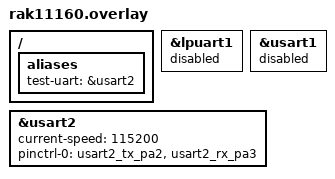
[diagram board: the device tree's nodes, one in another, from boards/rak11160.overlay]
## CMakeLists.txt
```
# SPDX-License-Identifier: Apache-2.0

cmake_minimum_required(VERSION 3.20.0)

find_package(Zephyr REQUIRED HINTS $ENV{ZEPHYR_BASE})
project(uart_sleep)

target_sources(app PRIVATE src/main.c)
target_sources_ifdef(CONFIG_BT_PERIPHERAL app PRIVATE src/rak_ble_peripheral.c)
if(CONFIG_USE_SEGGER_RTT AND CONFIG_BOARD_RAK11720)
  target_sources(app PRIVATE src/rtt.c)
endif()
```

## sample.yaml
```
sample:
  name: UART Sleep
tests:
  sample.basic.uart_sleep:
    platform_allow:
      - rak3172
      - rak4631
      - rak11160
    tags: rak
    build_only: true
  sample.basic.uart_sleep.ble:
    platform_allow:
      - rak11720
    extra_args: EXTRA_CONF_FILE=overlay_ble.conf
    tags: rak
    build_only: true
```

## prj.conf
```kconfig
CONFIG_SERIAL=y
CONFIG_UART_INTERRUPT_DRIVEN=y

CONFIG_GPIO=y
CONFIG_SPI=y
CONFIG_LORA=y

CONFIG_CONSOLE=n
CONFIG_UART_CONSOLE=n

CONFIG_PINCTRL=y
CONFIG_PM=y
CONFIG_PM_DEVICE=y

CONFIG_LOG=n
```

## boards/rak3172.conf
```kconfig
# Necessary options for low power consumption
CONFIG_PINCTRL=y
CONFIG_PM=y
CONFIG_PM_DEVICE=y
CONFIG_PM_DEVICE_RUNTIME=y
CONFIG_PM_DEVICE_SYSTEM_MANAGED=y

# Disable hardware features not in use
CONFIG_I2C=n
CONFIG_ADC=n
CONFIG_PWM=n
```

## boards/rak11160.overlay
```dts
/ {
	aliases {
		test-uart = &usart2;
	};
};

&lpuart1 {
	status = "disabled";
};

&usart1 {
	status = "disabled";
};

&usart2 {
	status = "okay";
	current-speed = <115200>;
	pinctrl-0 = <&usart2_tx_pa2 &usart2_rx_pa3>;
	pinctrl-names = "default";
};
```

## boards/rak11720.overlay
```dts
/ {
	aliases {
		test-uart = &uart0;
	};
};

&uart0 {
	status = "okay";
	current-speed = <115200>;
	pinctrl-0 = <&uart0_default>;
	pinctrl-1 = <&uart0_sleep>;
	pinctrl-names = "default", "sleep";
};

&uart1 {
	status = "disabled";
};
```

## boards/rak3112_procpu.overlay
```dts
/ {
	aliases {
		test-uart = &uart0;
	};
};

&usb_serial {
	status = "disabled";
};
```

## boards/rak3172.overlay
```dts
/ {
	chosen {
		zephyr,console = &lpuart1;
		zephyr,shell-uart = &lpuart1;
	};

	aliases {
		test-uart = &lpuart1;
	};
};

&lpuart1 {
	pinctrl-0 = <&lpuart1_tx_pa2 &lpuart1_rx_pa3>;
	pinctrl-names = "default";
	current-speed = <115200>;
	status = "okay";
};
```

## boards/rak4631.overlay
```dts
/ {
	aliases {
		test-uart = &uart1;
	};
};

&uart0 {
	status = "disabled";
};

&uart1 {
	compatible = "nordic,nrf-uarte";
	current-speed = <115200>;
	status = "okay";
	pinctrl-0 = <&uart1_default>;
	pinctrl-1 = <&uart1_sleep>;
	pinctrl-names = "default", "sleep";
};
```

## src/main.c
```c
#include <zephyr/kernel.h>
#include <zephyr/device.h>
#include <zephyr/drivers/uart.h>
#include <zephyr/pm/device.h>

#include "rak_ble_peripheral.h"

#include <zephyr/logging/log.h>
LOG_MODULE_REGISTER(main, LOG_LEVEL_INF);

/*
 * Get LoRa device
 */
static const struct device *lora_dev = DEVICE_DT_GET(DT_ALIAS(lora0));

/*
 * Get UART device
 */
static const struct device *const uart_dev = DEVICE_DT_GET(DT_ALIAS(test_uart));

/*
 * Print a null-terminated string character by character to the UART interface
 */
void print_uart(char *buf)
{
	int msg_len = strlen(buf);

	for (int i = 0; i < msg_len; i++) {
		uart_poll_out(uart_dev, buf[i]);
	}
}

int main(void)
{
	if (!device_is_ready(lora_dev)) {
		LOG_ERR("LoRa device not found!");
		return -1;
	}

	if (!device_is_ready(uart_dev)) {
		LOG_ERR("UART device not found!");
		return -1;
	}

#if defined(CONFIG_BT_PERIPHERAL)
	int ret = rak_ble_peripheral_init();
	if (ret) {
		LOG_ERR("Failed to init ble peripheral: %d", ret);
		return -1;
	}
#endif

	while (1) {
		pm_device_action_run(uart_dev, PM_DEVICE_ACTION_RESUME);
		print_uart("Hello! Uart Sleep Test.\r\n");
		pm_device_action_run(uart_dev, PM_DEVICE_ACTION_SUSPEND);

		k_msleep(10000);
	}

	return 0;
}
```

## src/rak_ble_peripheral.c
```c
#include <stdio.h>

#include <zephyr/kernel.h>
#include <zephyr/device.h>

#include <zephyr/bluetooth/bluetooth.h>
#include <zephyr/bluetooth/hci.h>
#include <zephyr/bluetooth/conn.h>
#include <zephyr/bluetooth/gatt.h>

#include "rak_ble_peripheral.h"

#include <zephyr/logging/log.h>
LOG_MODULE_REGISTER(ble_peripheral, LOG_LEVEL_INF);

#define DEVICE_NAME     CONFIG_BT_DEVICE_NAME
#define DEVICE_NAME_LEN (sizeof(DEVICE_NAME) - 1)

/* Advertising data */
static const struct bt_data ad[] = {
	BT_DATA_BYTES(BT_DATA_FLAGS, BT_LE_AD_NO_BREDR),
	BT_DATA_BYTES(BT_DATA_SVC_DATA16, 0xaa, 0xfe, /* Eddystone UUID */
		      0x10,                           /* Eddystone-URL frame type */
		      0x00,                           /* Calibrated Tx power at 0m */
		      0x01,                           /* URL Scheme Prefix https://www. */
		      'r', 'a', 'k', 'w', 'i', 'r', 'e', 'l', 'e', 's', 's', 0x07 /* .com */
		      )};

/* Scan response data */
static const struct bt_data sd[] = {BT_DATA(BT_DATA_NAME_COMPLETE, DEVICE_NAME, DEVICE_NAME_LEN)};

static void adv_stop_work_handler(struct k_work *work)
{
	LOG_INF("Advertising stopped");
	bt_le_adv_stop();
}
static K_WORK_DELAYABLE_DEFINE(adv_stop_work, adv_stop_work_handler);

static void adv_start_work_handler(struct k_work *work)
{
	bt_le_adv_stop();

	int err = bt_le_adv_start(BT_LE_ADV_NCONN_IDENTITY, ad, ARRAY_SIZE(ad), sd, ARRAY_SIZE(sd));
	if (err) {
		LOG_ERR("Advertising failed to start (err %d)", err);
		return;
	}

	LOG_INF("Advertising successfully started");
	k_work_reschedule(&adv_stop_work, K_SECONDS(1));
}
K_WORK_DEFINE(adv_start_work, adv_start_work_handler);

static void bt_ready_handler(int err)
{
	if (err) {
		LOG_ERR("Ble peripheral init failed (err %d)", err);
		return;
	}

	k_work_submit(&adv_start_work);
}

int rak_ble_peripheral_init(void)
{
	int err = bt_enable(bt_ready_handler);
	if (err) {
		LOG_ERR("Bluetooth init failed (err %d)", err);
		return err;
	}

	return err;
}
```
